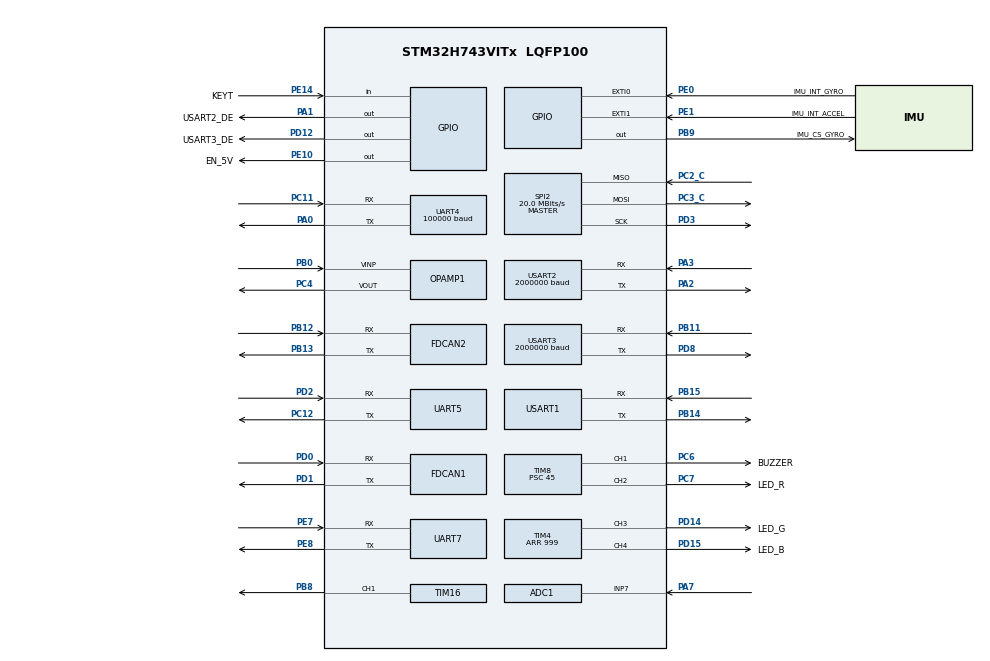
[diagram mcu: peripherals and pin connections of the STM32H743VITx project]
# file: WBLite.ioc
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ADC1.Channel-2\#ChannelRegularConversion=ADC_CHANNEL_7
ADC1.ClockPrescaler=ADC_CLOCK_ASYNC_DIV64
ADC1.NbrOfConversionFlag=1
ADC1.OffsetNumber-2\#ChannelRegularConversion=ADC_OFFSET_NONE
ADC1.OffsetSignedSaturation-2\#ChannelRegularConversion=DISABLE
ADC1.Rank-2\#ChannelRegularConversion=1
ADC1.SamplingTime-2\#ChannelRegularConversion=ADC_SAMPLETIME_810CYCLES_5
ADC1.master=1
CORTEX_M7.CPU_DCache=Enabled
CORTEX_M7.CPU_ICache=Enabled
Dma.MEMTOMEM.0.Direction=DMA_MEMORY_TO_MEMORY
Dma.MEMTOMEM.0.EventEnable=DISABLE
Dma.MEMTOMEM.0.FIFOMode=DMA_FIFOMODE_ENABLE
Dma.MEMTOMEM.0.FIFOThreshold=DMA_FIFO_THRESHOLD_FULL
Dma.MEMTOMEM.0.Instance=DMA2_Stream0
Dma.MEMTOMEM.0.MemBurst=DMA_MBURST_SINGLE
Dma.MEMTOMEM.0.MemDataAlignment=DMA_MDATAALIGN_BYTE
Dma.MEMTOMEM.0.MemInc=DMA_MINC_ENABLE
Dma.MEMTOMEM.0.Mode=DMA_NORMAL
Dma.MEMTOMEM.0.PeriphBurst=DMA_PBURST_SINGLE
Dma.MEMTOMEM.0.PeriphDataAlignment=DMA_PDATAALIGN_BYTE
Dma.MEMTOMEM.0.PeriphInc=DMA_PINC_ENABLE
Dma.MEMTOMEM.0.Polarity=HAL_DMAMUX_REQ_GEN_RISING
Dma.MEMTOMEM.0.Priority=DMA_PRIORITY_LOW
Dma.MEMTOMEM.0.RequestNumber=1
Dma.MEMTOMEM.0.SignalID=NONE
Dma.MEMTOMEM.0.SyncEnable=DISABLE
Dma.MEMTOMEM.0.SyncPolarity=HAL_DMAMUX_SYNC_NO_EVENT
Dma.MEMTOMEM.0.SyncRequestNumber=1
Dma.MEMTOMEM.0.SyncSignalID=NONE
Dma.Request0=MEMTOMEM
Dma.Request1=UART4_RX
Dma.Request10=USART3_RX
Dma.Request11=USART3_TX
Dma.Request2=USART2_RX
Dma.Request3=UART7_RX
Dma.Request4=UART7_TX
Dma.Request5=USART2_TX
Dma.Request6=USART1_RX
Dma.Request7=USART1_TX
Dma.Request8=UART5_RX
Dma.Request9=UART5_TX
Dma.UART4_RX.1.Direction=DMA_PERIPH_TO_MEMORY
Dma.UART4_RX.1.EventEnable=DISABLE
Dma.UART4_RX.1.FIFOMode=DMA_FIFOMODE_DISABLE
Dma.UART4_RX.1.Instance=DMA1_Stream0
Dma.UART4_RX.1.MemDataAlignment=DMA_MDATAALIGN_BYTE
Dma.UART4_RX.1.MemInc=DMA_MINC_ENABLE
Dma.UART4_RX.1.Mode=DMA_NORMAL
Dma.UART4_RX.1.PeriphDataAlignment=DMA_PDATAALIGN_BYTE
Dma.UART4_RX.1.PeriphInc=DMA_PINC_DISABLE
Dma.UART4_RX.1.Polarity=HAL_DMAMUX_REQ_GEN_RISING
Dma.UART4_RX.1.Priority=DMA_PRIORITY_LOW
Dma.UART4_RX.1.RequestNumber=1
Dma.UART4_RX.1.SignalID=NONE
Dma.UART4_RX.1.SyncEnable=DISABLE
Dma.UART4_RX.1.SyncPolarity=HAL_DMAMUX_SYNC_NO_EVENT
Dma.UART4_RX.1.SyncRequestNumber=1
Dma.UART4_RX.1.SyncSignalID=NONE
Dma.UART5_RX.8.Direction=DMA_PERIPH_TO_MEMORY
Dma.UART5_RX.8.EventEnable=DISABLE
Dma.UART5_RX.8.FIFOMode=DMA_FIFOMODE_DISABLE
Dma.UART5_RX.8.Instance=DMA1_Stream7
Dma.UART5_RX.8.MemDataAlignment=DMA_MDATAALIGN_BYTE
Dma.UART5_RX.8.MemInc=DMA_MINC_ENABLE
Dma.UART5_RX.8.Mode=DMA_NORMAL
Dma.UART5_RX.8.PeriphDataAlignment=DMA_PDATAALIGN_BYTE
Dma.UART5_RX.8.PeriphInc=DMA_PINC_DISABLE
Dma.UART5_RX.8.Polarity=HAL_DMAMUX_REQ_GEN_RISING
Dma.UART5_RX.8.Priority=DMA_PRIORITY_LOW
Dma.UART5_RX.8.RequestNumber=1
Dma.UART5_RX.8.SignalID=NONE
Dma.UART5_RX.8.SyncEnable=DISABLE
Dma.UART5_RX.8.SyncPolarity=HAL_DMAMUX_SYNC_NO_EVENT
Dma.UART5_RX.8.SyncRequestNumber=1
Dma.UART5_RX.8.SyncSignalID=NONE
Dma.UART5_TX.9.Direction=DMA_MEMORY_TO_PERIPH
Dma.UART5_TX.9.EventEnable=DISABLE
Dma.UART5_TX.9.FIFOMode=DMA_FIFOMODE_DISABLE
Dma.UART5_TX.9.Instance=DMA2_Stream1
Dma.UART5_TX.9.MemDataAlignment=DMA_MDATAALIGN_BYTE
Dma.UART5_TX.9.MemInc=DMA_MINC_ENABLE
Dma.UART5_TX.9.Mode=DMA_NORMAL
Dma.UART5_TX.9.PeriphDataAlignment=DMA_PDATAALIGN_BYTE
Dma.UART5_TX.9.PeriphInc=DMA_PINC_DISABLE
Dma.UART5_TX.9.Polarity=HAL_DMAMUX_REQ_GEN_RISING
Dma.UART5_TX.9.Priority=DMA_PRIORITY_LOW
Dma.UART5_TX.9.RequestNumber=1
Dma.UART5_TX.9.SignalID=NONE
Dma.UART5_TX.9.SyncEnable=DISABLE
Dma.UART5_TX.9.SyncPolarity=HAL_DMAMUX_SYNC_NO_EVENT
Dma.UART5_TX.9.SyncRequestNumber=1
Dma.UART5_TX.9.SyncSignalID=NONE
Dma.UART7_RX.3.Direction=DMA_PERIPH_TO_MEMORY
Dma.UART7_RX.3.EventEnable=DISABLE
Dma.UART7_RX.3.FIFOMode=DMA_FIFOMODE_DISABLE
Dma.UART7_RX.3.Instance=DMA1_Stream2
Dma.UART7_RX.3.MemDataAlignment=DMA_MDATAALIGN_BYTE
Dma.UART7_RX.3.MemInc=DMA_MINC_ENABLE
Dma.UART7_RX.3.Mode=DMA_NORMAL
Dma.UART7_RX.3.PeriphDataAlignment=DMA_PDATAALIGN_BYTE
Dma.UART7_RX.3.PeriphInc=DMA_PINC_DISABLE
Dma.UART7_RX.3.Polarity=HAL_DMAMUX_REQ_GEN_RISING
Dma.UART7_RX.3.Priority=DMA_PRIORITY_LOW
Dma.UART7_RX.3.RequestNumber=1
Dma.UART7_RX.3.SignalID=NONE
Dma.UART7_RX.3.SyncEnable=DISABLE
Dma.UART7_RX.3.SyncPolarity=HAL_DMAMUX_SYNC_NO_EVENT
Dma.UART7_RX.3.SyncRequestNumber=1
Dma.UART7_RX.3.SyncSignalID=NONE
Dma.UART7_TX.4.Direction=DMA_MEMORY_TO_PERIPH
Dma.UART7_TX.4.EventEnable=DISABLE
Dma.UART7_TX.4.FIFOMode=DMA_FIFOMODE_DISABLE
Dma.UART7_TX.4.Instance=DMA1_Stream3
Dma.UART7_TX.4.MemDataAlignment=DMA_MDATAALIGN_BYTE
Dma.UART7_TX.4.MemInc=DMA_MINC_ENABLE
Dma.UART7_TX.4.Mode=DMA_NORMAL
Dma.UART7_TX.4.PeriphDataAlignment=DMA_PDATAALIGN_BYTE
Dma.UART7_TX.4.PeriphInc=DMA_PINC_DISABLE
Dma.UART7_TX.4.Polarity=HAL_DMAMUX_REQ_GEN_RISING
Dma.UART7_TX.4.Priority=DMA_PRIORITY_LOW
Dma.UART7_TX.4.RequestNumber=1
Dma.UART7_TX.4.SignalID=NONE
Dma.UART7_TX.4.SyncEnable=DISABLE
Dma.UART7_TX.4.SyncPolarity=HAL_DMAMUX_SYNC_NO_EVENT
Dma.UART7_TX.4.SyncRequestNumber=1
Dma.UART7_TX.4.SyncSignalID=NONE
Dma.USART1_RX.6.Direction=DMA_PERIPH_TO_MEMORY
Dma.USART1_RX.6.EventEnable=DISABLE
Dma.USART1_RX.6.FIFOMode=DMA_FIFOMODE_DISABLE
Dma.USART1_RX.6.Instance=DMA1_Stream5
Dma.USART1_RX.6.MemDataAlignment=DMA_MDATAALIGN_BYTE
Dma.USART1_RX.6.MemInc=DMA_MINC_ENABLE
Dma.USART1_RX.6.Mode=DMA_NORMAL
Dma.USART1_RX.6.PeriphDataAlignment=DMA_PDATAALIGN_BYTE
Dma.USART1_RX.6.PeriphInc=DMA_PINC_DISABLE
Dma.USART1_RX.6.Polarity=HAL_DMAMUX_REQ_GEN_RISING
Dma.USART1_RX.6.Priority=DMA_PRIORITY_LOW
Dma.USART1_RX.6.RequestNumber=1
Dma.USART1_RX.6.SignalID=NONE
Dma.USART1_RX.6.SyncEnable=DISABLE
Dma.USART1_RX.6.SyncPolarity=HAL_DMAMUX_SYNC_NO_EVENT
Dma.USART1_RX.6.SyncRequestNumber=1
Dma.USART1_RX.6.SyncSignalID=NONE
Dma.USART1_TX.7.Direction=DMA_MEMORY_TO_PERIPH
Dma.USART1_TX.7.EventEnable=DISABLE
Dma.USART1_TX.7.FIFOMode=DMA_FIFOMODE_DISABLE
Dma.USART1_TX.7.Instance=DMA1_Stream6
Dma.USART1_TX.7.MemDataAlignment=DMA_MDATAALIGN_BYTE
Dma.USART1_TX.7.MemInc=DMA_MINC_ENABLE
Dma.USART1_TX.7.Mode=DMA_NORMAL
Dma.USART1_TX.7.PeriphDataAlignment=DMA_PDATAALIGN_BYTE
Dma.USART1_TX.7.PeriphInc=DMA_PINC_DISABLE
Dma.USART1_TX.7.Polarity=HAL_DMAMUX_REQ_GEN_RISING
Dma.USART1_TX.7.Priority=DMA_PRIORITY_LOW
Dma.USART1_TX.7.RequestNumber=1
Dma.USART1_TX.7.SignalID=NONE
Dma.USART1_TX.7.SyncEnable=DISABLE
Dma.USART1_TX.7.SyncPolarity=HAL_DMAMUX_SYNC_NO_EVENT
Dma.USART1_TX.7.SyncRequestNumber=1
Dma.USART1_TX.7.SyncSignalID=NONE
Dma.USART2_RX.2.Direction=DMA_PERIPH_TO_MEMORY
Dma.USART2_RX.2.EventEnable=DISABLE
Dma.USART2_RX.2.FIFOMode=DMA_FIFOMODE_DISABLE
Dma.USART2_RX.2.Instance=DMA1_Stream1
Dma.USART2_RX.2.MemDataAlignment=DMA_MDATAALIGN_BYTE
Dma.USART2_RX.2.MemInc=DMA_MINC_ENABLE
Dma.USART2_RX.2.Mode=DMA_NORMAL
Dma.USART2_RX.2.PeriphDataAlignment=DMA_PDATAALIGN_BYTE
Dma.USART2_RX.2.PeriphInc=DMA_PINC_DISABLE
Dma.USART2_RX.2.Polarity=HAL_DMAMUX_REQ_GEN_RISING
Dma.USART2_RX.2.Priority=DMA_PRIORITY_LOW
Dma.USART2_RX.2.RequestNumber=1
Dma.USART2_RX.2.SignalID=NONE
Dma.USART2_RX.2.SyncEnable=DISABLE
Dma.USART2_RX.2.SyncPolarity=HAL_DMAMUX_SYNC_NO_EVENT
Dma.USART2_RX.2.SyncRequestNumber=1
Dma.USART2_RX.2.SyncSignalID=NONE
Dma.USART2_TX.5.Direction=DMA_MEMORY_TO_PERIPH
Dma.USART2_TX.5.EventEnable=DISABLE
Dma.USART2_TX.5.FIFOMode=DMA_FIFOMODE_DISABLE
Dma.USART2_TX.5.Instance=DMA1_Stream4
Dma.USART2_TX.5.MemDataAlignment=DMA_MDATAALIGN_BYTE
Dma.USART2_TX.5.MemInc=DMA_MINC_ENABLE
Dma.USART2_TX.5.Mode=DMA_NORMAL
Dma.USART2_TX.5.PeriphDataAlignment=DMA_PDATAALIGN_BYTE
Dma.USART2_TX.5.PeriphInc=DMA_PINC_DISABLE
Dma.USART2_TX.5.Polarity=HAL_DMAMUX_REQ_GEN_RISING
Dma.USART2_TX.5.Priority=DMA_PRIORITY_LOW
Dma.USART2_TX.5.RequestNumber=1
Dma.USART2_TX.5.SignalID=NONE
Dma.USART2_TX.5.SyncEnable=DISABLE
Dma.USART2_TX.5.SyncPolarity=HAL_DMAMUX_SYNC_NO_EVENT
Dma.USART2_TX.5.SyncRequestNumber=1
Dma.USART2_TX.5.SyncSignalID=NONE
Dma.USART3_RX.10.Direction=DMA_PERIPH_TO_MEMORY
Dma.USART3_RX.10.EventEnable=DISABLE
Dma.USART3_RX.10.FIFOMode=DMA_FIFOMODE_DISABLE
Dma.USART3_RX.10.Instance=DMA2_Stream2
Dma.USART3_RX.10.MemDataAlignment=DMA_MDATAALIGN_BYTE
Dma.USART3_RX.10.MemInc=DMA_MINC_ENABLE
Dma.USART3_RX.10.Mode=DMA_NORMAL
Dma.USART3_RX.10.PeriphDataAlignment=DMA_PDATAALIGN_BYTE
Dma.USART3_RX.10.PeriphInc=DMA_PINC_DISABLE
Dma.USART3_RX.10.Polarity=HAL_DMAMUX_REQ_GEN_RISING
Dma.USART3_RX.10.Priority=DMA_PRIORITY_LOW
Dma.USART3_RX.10.RequestNumber=1
Dma.USART3_RX.10.SignalID=NONE
Dma.USART3_RX.10.SyncEnable=DISABLE
Dma.USART3_RX.10.SyncPolarity=HAL_DMAMUX_SYNC_NO_EVENT
Dma.USART3_RX.10.SyncRequestNumber=1
Dma.USART3_RX.10.SyncSignalID=NONE
Dma.USART3_TX.11.Direction=DMA_MEMORY_TO_PERIPH
Dma.USART3_TX.11.EventEnable=DISABLE
Dma.USART3_TX.11.FIFOMode=DMA_FIFOMODE_DISABLE
Dma.USART3_TX.11.Instance=DMA2_Stream3
Dma.USART3_TX.11.MemDataAlignment=DMA_MDATAALIGN_BYTE
Dma.USART3_TX.11.MemInc=DMA_MINC_ENABLE
Dma.USART3_TX.11.Mode=DMA_NORMAL
Dma.USART3_TX.11.PeriphDataAlignment=DMA_PDATAALIGN_BYTE
Dma.USART3_TX.11.PeriphInc=DMA_PINC_DISABLE
Dma.USART3_TX.11.Polarity=HAL_DMAMUX_REQ_GEN_RISING
Dma.USART3_TX.11.Priority=DMA_PRIORITY_LOW
Dma.USART3_TX.11.RequestNumber=1
Dma.USART3_TX.11.SignalID=NONE
Dma.USART3_TX.11.SyncEnable=DISABLE
Dma.USART3_TX.11.SyncPolarity=HAL_DMAMUX_SYNC_NO_EVENT
Dma.USART3_TX.11.SyncRequestNumber=1
Dma.USART3_TX.11.SyncSignalID=NONE
FDCAN1.CalculateBaudRateNominal=1000000
FDCAN1.CalculateTimeBitNominal=1000
FDCAN1.CalculateTimeQuantumNominal=100.0
FDCAN1.DataPrescaler=6
FDCAN1.DataTimeSeg1=4
FDCAN1.DataTimeSeg2=5
FDCAN1.NominalPrescaler=6
FDCAN1.NominalSyncJumpWidth=1
FDCAN1.NominalTimeSeg1=4
FDCAN1.NominalTimeSeg2=5
FDCAN1.RxFifo0ElmtsNbr=32
FDCAN1.StdFiltersNbr=1
FDCAN1.TxFifoQueueElmtsNbr=32
FDCAN2.CalculateBaudRateNominal=1000000
FDCAN2.CalculateTimeBitNominal=1000
FDCAN2.CalculateTimeQuantumNominal=100.0
FDCAN2.DataPrescaler=6
FDCAN2.DataTimeSeg1=4
FDCAN2.DataTimeSeg2=5
FDCAN2.MessageRAMOffset=0x406
FDCAN2.NominalPrescaler=6
FDCAN2.NominalTimeSeg1=4
FDCAN2.NominalTimeSeg2=5
FDCAN2.RxFifo1ElmtsNbr=32
FDCAN2.StdFiltersNbr=1
FDCAN2.TxFifoQueueElmtsNbr=32
Mcu.Family=STM32H7
Mcu.Name=STM32H743VITx
Mcu.Package=LQFP100
NVIC.DMA1_Stream0_IRQn=true\:0\:0\:false\:false\:false\:true\:false\:true\:true
NVIC.DMA1_Stream1_IRQn=true\:0\:0\:false\:false\:false\:true\:false\:true\:true
NVIC.DMA1_Stream2_IRQn=true\:0\:0\:false\:false\:false\:true\:false\:true\:true
NVIC.DMA1_Stream3_IRQn=true\:0\:0\:false\:false\:false\:true\:false\:true\:true
NVIC.DMA1_Stream4_IRQn=true\:0\:0\:false\:false\:false\:true\:false\:true\:true
NVIC.DMA1_Stream5_IRQn=true\:0\:0\:false\:false\:false\:true\:false\:true\:true
NVIC.DMA1_Stream6_IRQn=true\:0\:0\:false\:false\:false\:true\:false\:true\:true
NVIC.DMA1_Stream7_IRQn=true\:0\:0\:false\:false\:false\:true\:false\:true\:true
NVIC.DMA2_Stream1_IRQn=true\:0\:0\:false\:false\:false\:true\:false\:true\:true
NVIC.DMA2_Stream2_IRQn=true\:0\:0\:false\:false\:false\:true\:false\:true\:true
NVIC.DMA2_Stream3_IRQn=true\:0\:0\:false\:false\:false\:true\:false\:true\:true
NVIC.EXTI0_IRQn=true\:0\:0\:false\:false\:false\:false\:true\:true\:false
NVIC.EXTI1_IRQn=true\:0\:0\:false\:false\:false\:false\:true\:true\:false
NVIC.FDCAN1_IT0_IRQn=true\:0\:0\:false\:false\:true\:false\:true\:true\:true
NVIC.FDCAN1_IT1_IRQn=true\:0\:0\:false\:false\:true\:false\:true\:true\:true
NVIC.FDCAN2_IT0_IRQn=true\:0\:0\:false\:false\:true\:false\:true\:true\:true
NVIC.FDCAN2_IT1_IRQn=true\:0\:0\:false\:false\:true\:false\:true\:true\:true
NVIC.PriorityGroup=NVIC_PRIORITYGROUP_4
NVIC.TIM17_IRQn=true\:15\:0\:false\:false\:true\:false\:false\:true\:true
NVIC.TimeBase=TIM17_IRQn
NVIC.TimeBaseIP=TIM17
NVIC.UART4_IRQn=true\:0\:0\:false\:false\:false\:false\:true\:true\:true
NVIC.UART5_IRQn=true\:0\:0\:false\:false\:false\:false\:true\:true\:true
NVIC.UART7_IRQn=true\:0\:0\:false\:false\:false\:false\:true\:true\:true
NVIC.USART1_IRQn=true\:0\:0\:false\:false\:false\:false\:true\:true\:true
NVIC.USART2_IRQn=true\:0\:0\:false\:false\:false\:false\:true\:true\:true
NVIC.USART3_IRQn=true\:0\:0\:false\:false\:false\:false\:true\:true\:true
PA0.Mode=Asynchronous
PA0.PinAttribute=Free
PA0.Signal=UART4_TX
PA1.GPIO_Label=USART2_DE
PA1.GPIO_Speed=GPIO_SPEED_FREQ_VERY_HIGH
PA1.PinAttribute=Free
PA1.PinState=GPIO_PIN_RESET
PA1.Signal=GPIO_Output
PA13\ (JTMS/SWDIO).Mode=Serial_Wire
PA13\ (JTMS/SWDIO).Signal=DEBUG_JTMS-SWDIO
PA14\ (JTCK/SWCLK).Mode=Serial_Wire
PA14\ (JTCK/SWCLK).Signal=DEBUG_JTCK-SWCLK
PA2.Mode=Asynchronous
PA2.Signal=USART2_TX
PA3.Mode=Asynchronous
PA3.Signal=USART2_RX
PA7.Signal=ADCx_INP7
PB0.Mode=Follower
PB0.Signal=OPAMP1_VINP
PB11.Mode=Asynchronous
PB11.PinAttribute=Free
PB11.Signal=USART3_RX
PB12.Mode=FDCAN_Activate
PB12.PinAttribute=Free
PB12.Signal=FDCAN2_RX
PB13.Mode=FDCAN_Activate
PB13.Signal=FDCAN2_TX
PB14.Mode=Asynchronous
PB14.Signal=USART1_TX
PB15.Mode=Asynchronous
PB15.Signal=USART1_RX
PB8.GPIO_PuPd=GPIO_PULLDOWN
PB8.Signal=S_TIM16_CH1
PB9.GPIO_Label=IMU_CS_GYRO
PB9.GPIO_PuPd=GPIO_NOPULL
PB9.GPIO_Speed=GPIO_SPEED_FREQ_VERY_HIGH
PB9.PinState=GPIO_PIN_SET
PB9.Signal=GPIO_Output
PC11.Mode=Asynchronous
PC11.Signal=UART4_RX
PC12.Mode=Asynchronous
PC12.Signal=UART5_TX
PC2_C.GPIO_Speed=GPIO_SPEED_FREQ_VERY_HIGH
PC2_C.Mode=Full_Duplex_Master
PC2_C.PinAttribute=Free
PC2_C.Signal=SPI2_MISO
PC3_C.GPIO_Speed=GPIO_SPEED_FREQ_VERY_HIGH
PC3_C.Mode=Full_Duplex_Master
PC3_C.PinAttribute=Free
PC3_C.Signal=SPI2_MOSI
PC4.Mode=Follower
PC4.Signal=OPAMP1_VOUT
PC6.GPIO_Label=BUZZER
PC6.Signal=S_TIM8_CH1
PC7.GPIO_Label=LED_R
PC7.Signal=S_TIM8_CH2
PD0.Mode=FDCAN_Activate
PD0.Signal=FDCAN1_RX
PD1.Mode=FDCAN_Activate
PD1.Signal=FDCAN1_TX
PD12.GPIO_Label=USART3_DE
PD12.GPIO_Speed=GPIO_SPEED_FREQ_VERY_HIGH
PD12.Signal=GPIO_Output
PD14.GPIO_Label=LED_G
PD14.Signal=S_TIM4_CH3
PD15.GPIO_Label=LED_B
PD15.Signal=S_TIM4_CH4
PD2.Mode=Asynchronous
PD2.Signal=UART5_RX
PD3.GPIO_Speed=GPIO_SPEED_FREQ_VERY_HIGH
PD3.Mode=Full_Duplex_Master
PD3.PinAttribute=Free
PD3.Signal=SPI2_SCK
PD8.Mode=Asynchronous
PD8.Signal=USART3_TX
PE0.GPIO_Label=IMU_INT_GYRO
PE0.GPIO_ModeDefaultEXTI=GPIO_MODE_IT_FALLING
PE0.GPIO_PuPd=GPIO_PULLUP
PE0.Signal=GPXTI0
PE1.GPIO_Label=IMU_INT_ACCEL
PE1.GPIO_ModeDefaultEXTI=GPIO_MODE_IT_FALLING
PE1.GPIO_PuPd=GPIO_PULLUP
PE1.Signal=GPXTI1
PE10.GPIO_Label=EN_5V
PE10.PinAttribute=Free
PE10.Signal=GPIO_Output
PE14.GPIO_Label=KEYT
PE14.PinAttribute=Free
PE14.Signal=GPIO_Input
PE7.Mode=Asynchronous
PE7.Signal=UART7_RX
PE8.Mode=Asynchronous
PE8.Signal=UART7_TX
PH0-OSC_IN\ (PH0).Mode=HSE-External-Oscillator
PH0-OSC_IN\ (PH0).PinAttribute=Free
PH0-OSC_IN\ (PH0).Signal=RCC_OSC_IN
PH1-OSC_OUT\ (PH1).Mode=HSE-External-Oscillator
PH1-OSC_OUT\ (PH1).PinAttribute=Free
PH1-OSC_OUT\ (PH1).Signal=RCC_OSC_OUT
ProjectManager.HeapSize=0x800
ProjectManager.StackSize=0x800
ProjectManager.TargetToolchain=MDK-ARM V5.32
RCC.ADCCLockSelection=RCC_ADCCLKSOURCE_CLKP
RCC.ADCFreq_Value=64000000
RCC.APB1Freq_Value=120000000
RCC.APB2Freq_Value=120000000
RCC.APB3Freq_Value=120000000
RCC.APB4Freq_Value=120000000
RCC.CortexFreq_Value=480000000
RCC.D1PPRE=RCC_APB3_DIV2
RCC.D2PPRE1=RCC_APB1_DIV2
RCC.D2PPRE2=RCC_APB2_DIV2
RCC.D3PPRE=RCC_APB4_DIV2
RCC.DIVM1=1
RCC.DIVM2=1
RCC.DIVM3=4
RCC.DIVN1=120
RCC.DIVN2=120
RCC.DIVN3=80
RCC.DIVP3=4
RCC.DIVQ1=20
RCC.DIVQ2=16
RCC.DIVQ3=4
RCC.FDCANCLockSelection=RCC_FDCANCLKSOURCE_PLL2
RCC.HCLKFreq_Value=240000000
RCC.HPRE=RCC_HCLK_DIV2
RCC.HSE_VALUE=8000000
RCC.PLL2FRACN=0
RCC.PLL2_VCI_Range-AdvancedSettings=RCC_PLL2VCIRANGE_3
RCC.PLL2_VCO_SEL-AdvancedSettings=RCC_PLL2VCOWIDE
RCC.PLL3FRACN=0
RCC.PLLFRACN=0
RCC.PLLSourceVirtual=RCC_PLLSOURCE_HSE
RCC.PWR_Regulator_Voltage_Scale=PWR_REGULATOR_VOLTAGE_SCALE0
RCC.ProductRev=revV
RCC.SPI123CLockSelection=RCC_SPI123CLKSOURCE_PLL3
RCC.SYSCLKFreq_VALUE=480000000
RCC.SYSCLKSource=RCC_SYSCLKSOURCE_PLLCLK
RCC.USBFreq_Value=48000000
SH.ADCx_INP7.0=ADC1_INP7,IN7-Single-Ended
SH.S_TIM16_CH1.0=TIM16_CH1,PWM Generation1 CH1
SH.S_TIM4_CH3.0=TIM4_CH3,PWM Generation3 CH3
SH.S_TIM4_CH4.0=TIM4_CH4,PWM Generation4 CH4
SH.S_TIM8_CH1.0=TIM8_CH1,PWM Generation1 CH1
SH.S_TIM8_CH2.0=TIM8_CH2,PWM Generation2 CH2
SPI2.BaudRatePrescaler=SPI_BAUDRATEPRESCALER_2
SPI2.CalculateBaudRate=20.0 MBits/s
SPI2.DataSize=SPI_DATASIZE_8BIT
SPI2.Direction=SPI_DIRECTION_2LINES
SPI2.Mode=SPI_MODE_MASTER
SPI2.NSSPMode=SPI_NSS_PULSE_DISABLE
SPI2.VirtualType=VM_MASTER
STMicroelectronics.X-CUBE-AZRTOS-H7.3.1.0.TX_APP_GENERATE_INIT_CODE=false
STMicroelectronics.X-CUBE-AZRTOS-H7.3.1.0.TX_APP_MEM_POOL_SIZE=2048
STMicroelectronics.X-CUBE-AZRTOS-H7.3.1.0.TX_DISABLE_PREEMPTION_THRESHOLD=0
STMicroelectronics.X-CUBE-AZRTOS-H7.3.1.0.TX_DISABLE_REDUNDANT_CLEARING=0
STMicroelectronics.X-CUBE-AZRTOS-H7.3.1.0.TX_DISABLE_STACK_FILLING=1
STMicroelectronics.X-CUBE-AZRTOS-H7.3.1.0.TX_INLINE_THREAD_RESUME_SUSPEND=1
STMicroelectronics.X-CUBE-AZRTOS-H7.3.1.0.TX_NOT_INTERRUPTABLE=0
STMicroelectronics.X-CUBE-AZRTOS-H7.3.1.0.TX_REACTIVATE_INLINE=1
STMicroelectronics.X-CUBE-AZRTOS-H7.3.1.0.TX_TIMER_PROCESS_IN_ISR=1
STMicroelectronics.X-CUBE-AZRTOS-H7.3.1.0.TX_TIMER_TICKS_PER_SECOND=1000
STMicroelectronics.X-CUBE-AZRTOS-H7.3.1.0.ThreadXCcRTOSJjThreadXJjCore=true
STMicroelectronics.X-CUBE-AZRTOS-H7.3.1.0.USBX_DEVICE_SYS_SIZE=10240
STMicroelectronics.X-CUBE-AZRTOS-H7.3.1.0.UX_DEVICE_APP_MEM_POOL_SIZE=20480
STMicroelectronics.X-CUBE-AZRTOS-H7.3.1.0_IsAnAzureRtosMw=true
TIM16.Channel=TIM_CHANNEL_1
TIM16.Period=999
TIM4.Channel-PWM\ Generation3\ CH3=TIM_CHANNEL_3
TIM4.Channel-PWM\ Generation4\ CH4=TIM_CHANNEL_4
TIM4.Period=999
TIM4.Pulse-PWM\ Generation4\ CH4=999
TIM8.Channel-PWM\ Generation1\ CH1=TIM_CHANNEL_1
TIM8.Channel-PWM\ Generation2\ CH2=TIM_CHANNEL_2
TIM8.Period=999
TIM8.Prescaler=45
TIM8.Pulse-PWM\ Generation2\ CH2=799
UART4.BaudRate=100000
UART4.FIFOMode=FIFOMODE_DISABLE
UART4.Mode=MODE_RX
UART4.Parity=PARITY_EVEN
UART4.RxPinLevelInvertParam=UART_ADVFEATURE_RXINV_ENABLE
UART4.StopBits=UART_STOPBITS_2
UART4.WordLength=WORDLENGTH_9B
USART1.VirtualMode-Asynchronous=VM_ASYNC
USART2.BaudRate=2000000
USART2.VirtualMode-Asynchronous=VM_ASYNC
USART3.BaudRate=2000000
USART3.VirtualMode-Asynchronous=VM_ASYNC
VP_STMicroelectronics.X-CUBE-AZRTOS-H7_VS_RTOSJjThreadX_6.2.0_3.1.0.Mode=RTOSJjThreadX
VP_SYS_VS_tim17.Mode=TIM17
VP_TIM16_VS_ClockSourceINT.Mode=Enable_Timer
VP_TIM4_VS_ClockSourceINT.Mode=Internal
VP_TIM8_VS_ClockSourceINT.Mode=Internal
board=custom

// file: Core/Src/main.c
/* USER CODE BEGIN Header */
/**
  ******************************************************************************
  * @file           : main.c
  * @brief          : Main program body
  ******************************************************************************
  * @attention
  *
  * Copyright (c) 2023 STMicroelectronics.
  * All rights reserved.
  *
  * This software is licensed under terms that can be found in the LICENSE file
  * in the root directory of this software component.
  * If no LICENSE file comes with this software, it is provided AS-IS.
  *
  ******************************************************************************
  */
/* USER CODE END Header */
#include "app_threadx.h"
#include "main.h"
#include "adc.h"
#include "dma.h"
#include "fdcan.h"
#include "opamp.h"
#include "spi.h"
#include "tim.h"
#include "usart.h"
#include "gpio.h"

void SystemClock_Config(void);
void PeriphCommonClock_Config(void);

int main(void)
{
  /* USER CODE BEGIN 1 */

  /*Move NVIC map tp DTCM*/
  uint32_t *DestAddr = (uint32_t *)D1_DTCMRAM_BASE;
  const uint32_t *SouceAddr = (const uint32_t *)FLASH_BANK1_BASE;
  memcpy(DestAddr, SouceAddr, 0x400);
  SCB->VTOR = D1_DTCMRAM_BASE;

  /* USER CODE END 1 */

  /* Enable I-Cache---------------------------------------------------------*/
  SCB_EnableICache();

  /* Enable D-Cache---------------------------------------------------------*/
  SCB_EnableDCache();

  /* MCU Configuration--------------------------------------------------------*/

  /* Reset of all peripherals, Initializes the Flash interface and the Systick. */
  HAL_Init();

  /* Configure the system clock */
  SystemClock_Config();

/* Configure the peripherals common clocks */
  PeriphCommonClock_Config();

  /* Initialize all configured peripherals */
  MX_DMA_Init();
  MX_GPIO_Init();
  MX_SPI2_Init();
  MX_UART4_Init();
  MX_UART7_Init();
  MX_USART2_UART_Init();
  MX_USART1_UART_Init();
  MX_TIM16_Init();
  MX_UART5_Init();
  MX_TIM4_Init();
  MX_TIM8_Init();
  MX_USART3_UART_Init();
  MX_FDCAN1_Init();
  MX_FDCAN2_Init();
  MX_ADC1_Init();
  MX_OPAMP1_Init();

  MX_ThreadX_Init();

  /* We should never get here as control is now taken by the scheduler */
  /* Infinite loop */
  while (1)
  {

  }
}

void SystemClock_Config(void)
{
  LL_FLASH_SetLatency(LL_FLASH_LATENCY_4);
  while(LL_FLASH_GetLatency()!= LL_FLASH_LATENCY_4)
  {
  }
  LL_PWR_ConfigSupply(LL_PWR_LDO_SUPPLY);
  LL_PWR_SetRegulVoltageScaling(LL_PWR_REGU_VOLTAGE_SCALE0);
  while (LL_PWR_IsActiveFlag_VOS() == 0)
  {
  }
  LL_RCC_HSE_Enable();

   /* Wait till HSE is ready */
  while(LL_RCC_HSE_IsReady() != 1)
  {

  }
  LL_RCC_HSI_Enable();

   /* Wait till HSI is ready */
  while(LL_RCC_HSI_IsReady() != 1)
  {

  }
  LL_RCC_HSI_SetCalibTrimming(64);
  LL_RCC_HSI_SetDivider(LL_RCC_HSI_DIV1);
  LL_RCC_PLL_SetSource(LL_RCC_PLLSOURCE_HSE);
  LL_RCC_PLL1P_Enable();
  LL_RCC_PLL1R_Enable();
  LL_RCC_PLL1_SetVCOInputRange(LL_RCC_PLLINPUTRANGE_8_16);
  LL_RCC_PLL1_SetVCOOutputRange(LL_RCC_PLLVCORANGE_WIDE);
  LL_RCC_PLL1_SetM(1);
  LL_RCC_PLL1_SetN(120);
  LL_RCC_PLL1_SetP(2);
  LL_RCC_PLL1_SetQ(20);
  LL_RCC_PLL1_SetR(2);
  LL_RCC_PLL1_Enable();

   /* Wait till PLL is ready */
  while(LL_RCC_PLL1_IsReady() != 1)
  {
  }

   /* Intermediate AHB prescaler 2 when target frequency clock is higher than 80 MHz */
   LL_RCC_SetAHBPrescaler(LL_RCC_AHB_DIV_2);

  LL_RCC_SetSysClkSource(LL_RCC_SYS_CLKSOURCE_PLL1);

   /* Wait till System clock is ready */
  while(LL_RCC_GetSysClkSource() != LL_RCC_SYS_CLKSOURCE_STATUS_PLL1)
  {

  }
  LL_RCC_SetSysPrescaler(LL_RCC_SYSCLK_DIV_1);
  LL_RCC_SetAHBPrescaler(LL_RCC_AHB_DIV_2);
  LL_RCC_SetAPB1Prescaler(LL_RCC_APB1_DIV_2);
  LL_RCC_SetAPB2Prescaler(LL_RCC_APB2_DIV_2);
  LL_RCC_SetAPB3Prescaler(LL_RCC_APB3_DIV_2);
  LL_RCC_SetAPB4Prescaler(LL_RCC_APB4_DIV_2);
  LL_SetSystemCoreClock(480000000);

   /* Update the time base */
  if (HAL_InitTick (TICK_INT_PRIORITY) != HAL_OK)
  {
    Error_Handler();
  }
}

void PeriphCommonClock_Config(void)
{
  LL_RCC_PLL2Q_Enable();
  LL_RCC_PLL2_SetVCOInputRange(LL_RCC_PLLINPUTRANGE_8_16);
  LL_RCC_PLL2_SetVCOOutputRange(LL_RCC_PLLVCORANGE_WIDE);
  LL_RCC_PLL2_SetM(1);
  LL_RCC_PLL2_SetN(120);
  LL_RCC_PLL2_SetP(2);
  LL_RCC_PLL2_SetQ(16);
  LL_RCC_PLL2_SetR(2);
  LL_RCC_PLL2_Enable();

   /* Wait till PLL is ready */
  while(LL_RCC_PLL2_IsReady() != 1)
  {
  }

  LL_RCC_PLL3P_Enable();
  LL_RCC_PLL3_SetVCOInputRange(LL_RCC_PLLINPUTRANGE_2_4);
  LL_RCC_PLL3_SetVCOOutputRange(LL_RCC_PLLVCORANGE_MEDIUM);
  LL_RCC_PLL3_SetM(4);
  LL_RCC_PLL3_SetN(80);
  LL_RCC_PLL3_SetP(4);
  LL_RCC_PLL3_SetQ(4);
  LL_RCC_PLL3_SetR(2);
  LL_RCC_PLL3_Enable();

   /* Wait till PLL is ready */
  while(LL_RCC_PLL3_IsReady() != 1)
  {
  }

  LL_RCC_SetCLKPClockSource(LL_RCC_CLKP_CLKSOURCE_HSI);
}

void HAL_TIM_PeriodElapsedCallback(TIM_HandleTypeDef *htim)
{
  if (htim->Instance == TIM17) {
    HAL_IncTick();
  }
}

void Error_Handler(void)
{
  __disable_irq();
  while (1)
  {
  }
}
